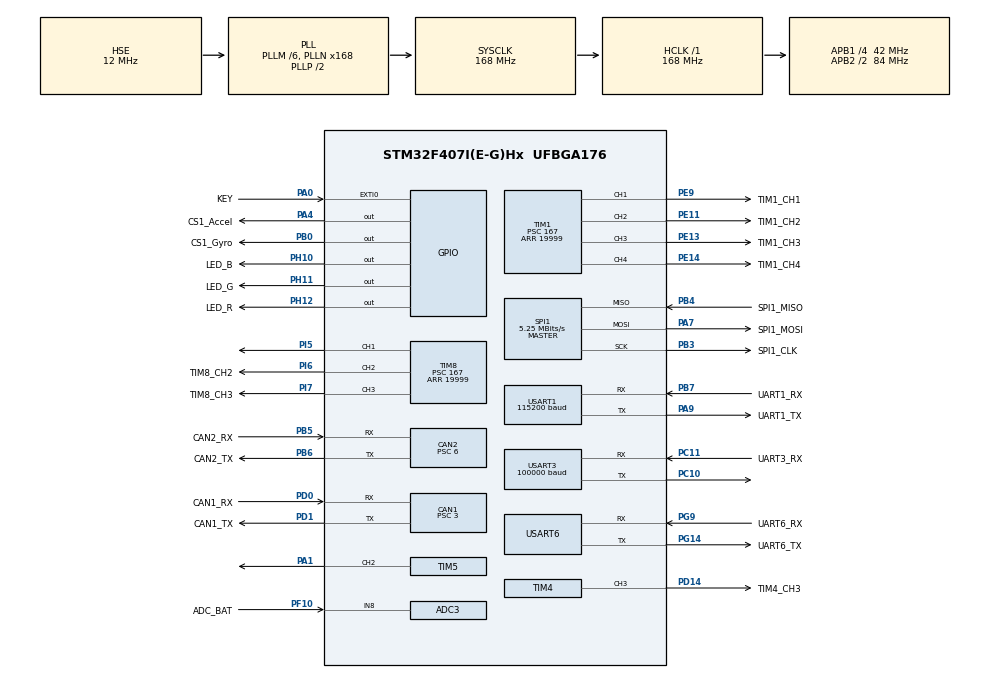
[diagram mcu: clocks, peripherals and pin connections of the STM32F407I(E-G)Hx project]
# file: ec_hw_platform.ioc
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ADC1.Channel-1\#ChannelRegularConversion=ADC_CHANNEL_TEMPSENSOR
ADC1.NbrOfConversionFlag=1
ADC1.Rank-1\#ChannelRegularConversion=1
ADC1.SamplingTime-1\#ChannelRegularConversion=ADC_SAMPLETIME_3CYCLES
ADC1.master=1
ADC3.Channel-4\#ChannelRegularConversion=ADC_CHANNEL_8
ADC3.EnableAnalogWatchDog=false
ADC3.ExternalTrigConv=ADC_EXTERNALTRIGCONV_T2_TRGO
ADC3.NbrOfConversionFlag=1
ADC3.Rank-4\#ChannelRegularConversion=1
ADC3.SamplingTime-4\#ChannelRegularConversion=ADC_SAMPLETIME_3CYCLES
CAN1.ABOM=ENABLE
CAN1.BS1=CAN_BS1_10TQ
CAN1.BS2=CAN_BS2_3TQ
CAN1.CalculateBaudRate=1000000
CAN1.CalculateTimeBit=1000
CAN1.CalculateTimeQuantum=71.42857142857143
CAN1.Prescaler=3
CAN2.ABOM=ENABLE
CAN2.BS1=CAN_BS1_3TQ
CAN2.BS2=CAN_BS2_3TQ
CAN2.CalculateBaudRate=1000000
CAN2.CalculateTimeBit=1000
CAN2.CalculateTimeQuantum=142.85714285714286
CAN2.Prescaler=6
Dma.Request0=USART1_TX
Dma.Request1=USART1_RX
Dma.Request2=USART6_RX
Dma.Request3=USART6_TX
Dma.Request4=SPI1_RX
Dma.Request5=SPI1_TX
Dma.Request6=USART3_RX
Dma.Request7=USART3_TX
Dma.SPI1_RX.4.Direction=DMA_PERIPH_TO_MEMORY
Dma.SPI1_RX.4.FIFOMode=DMA_FIFOMODE_DISABLE
Dma.SPI1_RX.4.Instance=DMA2_Stream0
Dma.SPI1_RX.4.MemDataAlignment=DMA_MDATAALIGN_BYTE
Dma.SPI1_RX.4.MemInc=DMA_MINC_ENABLE
Dma.SPI1_RX.4.Mode=DMA_NORMAL
Dma.SPI1_RX.4.PeriphDataAlignment=DMA_PDATAALIGN_BYTE
Dma.SPI1_RX.4.PeriphInc=DMA_PINC_DISABLE
Dma.SPI1_RX.4.Priority=DMA_PRIORITY_LOW
Dma.SPI1_TX.5.Direction=DMA_MEMORY_TO_PERIPH
Dma.SPI1_TX.5.FIFOMode=DMA_FIFOMODE_DISABLE
Dma.SPI1_TX.5.Instance=DMA2_Stream3
Dma.SPI1_TX.5.MemDataAlignment=DMA_MDATAALIGN_BYTE
Dma.SPI1_TX.5.MemInc=DMA_MINC_ENABLE
Dma.SPI1_TX.5.Mode=DMA_NORMAL
Dma.SPI1_TX.5.PeriphDataAlignment=DMA_PDATAALIGN_BYTE
Dma.SPI1_TX.5.PeriphInc=DMA_PINC_DISABLE
Dma.SPI1_TX.5.Priority=DMA_PRIORITY_LOW
Dma.USART1_RX.1.Direction=DMA_PERIPH_TO_MEMORY
Dma.USART1_RX.1.FIFOMode=DMA_FIFOMODE_DISABLE
Dma.USART1_RX.1.Instance=DMA2_Stream2
Dma.USART1_RX.1.MemDataAlignment=DMA_MDATAALIGN_BYTE
Dma.USART1_RX.1.MemInc=DMA_MINC_ENABLE
Dma.USART1_RX.1.Mode=DMA_NORMAL
Dma.USART1_RX.1.PeriphDataAlignment=DMA_PDATAALIGN_BYTE
Dma.USART1_RX.1.PeriphInc=DMA_PINC_DISABLE
Dma.USART1_RX.1.Priority=DMA_PRIORITY_LOW
Dma.USART1_TX.0.Direction=DMA_MEMORY_TO_PERIPH
Dma.USART1_TX.0.FIFOMode=DMA_FIFOMODE_DISABLE
Dma.USART1_TX.0.Instance=DMA2_Stream7
Dma.USART1_TX.0.MemDataAlignment=DMA_MDATAALIGN_BYTE
Dma.USART1_TX.0.MemInc=DMA_MINC_ENABLE
Dma.USART1_TX.0.Mode=DMA_NORMAL
Dma.USART1_TX.0.PeriphDataAlignment=DMA_PDATAALIGN_BYTE
Dma.USART1_TX.0.PeriphInc=DMA_PINC_DISABLE
Dma.USART1_TX.0.Priority=DMA_PRIORITY_LOW
Dma.USART3_RX.6.Direction=DMA_PERIPH_TO_MEMORY
Dma.USART3_RX.6.FIFOMode=DMA_FIFOMODE_DISABLE
Dma.USART3_RX.6.Instance=DMA1_Stream1
Dma.USART3_RX.6.MemDataAlignment=DMA_MDATAALIGN_BYTE
Dma.USART3_RX.6.MemInc=DMA_MINC_ENABLE
Dma.USART3_RX.6.Mode=DMA_NORMAL
Dma.USART3_RX.6.PeriphDataAlignment=DMA_PDATAALIGN_BYTE
Dma.USART3_RX.6.PeriphInc=DMA_PINC_DISABLE
Dma.USART3_RX.6.Priority=DMA_PRIORITY_LOW
Dma.USART3_TX.7.Direction=DMA_MEMORY_TO_PERIPH
Dma.USART3_TX.7.FIFOMode=DMA_FIFOMODE_DISABLE
Dma.USART3_TX.7.Instance=DMA1_Stream3
Dma.USART3_TX.7.MemDataAlignment=DMA_MDATAALIGN_BYTE
Dma.USART3_TX.7.MemInc=DMA_MINC_ENABLE
Dma.USART3_TX.7.Mode=DMA_NORMAL
Dma.USART3_TX.7.PeriphDataAlignment=DMA_PDATAALIGN_BYTE
Dma.USART3_TX.7.PeriphInc=DMA_PINC_DISABLE
Dma.USART3_TX.7.Priority=DMA_PRIORITY_LOW
Dma.USART6_RX.2.Direction=DMA_PERIPH_TO_MEMORY
Dma.USART6_RX.2.FIFOMode=DMA_FIFOMODE_DISABLE
Dma.USART6_RX.2.Instance=DMA2_Stream1
Dma.USART6_RX.2.MemDataAlignment=DMA_MDATAALIGN_BYTE
Dma.USART6_RX.2.MemInc=DMA_MINC_ENABLE
Dma.USART6_RX.2.Mode=DMA_NORMAL
Dma.USART6_RX.2.PeriphDataAlignment=DMA_PDATAALIGN_BYTE
Dma.USART6_RX.2.PeriphInc=DMA_PINC_DISABLE
Dma.USART6_RX.2.Priority=DMA_PRIORITY_LOW
Dma.USART6_TX.3.Direction=DMA_MEMORY_TO_PERIPH
Dma.USART6_TX.3.FIFOMode=DMA_FIFOMODE_DISABLE
Dma.USART6_TX.3.Instance=DMA2_Stream6
Dma.USART6_TX.3.MemDataAlignment=DMA_MDATAALIGN_BYTE
Dma.USART6_TX.3.MemInc=DMA_MINC_ENABLE
Dma.USART6_TX.3.Mode=DMA_NORMAL
Dma.USART6_TX.3.PeriphDataAlignment=DMA_PDATAALIGN_BYTE
Dma.USART6_TX.3.PeriphInc=DMA_PINC_DISABLE
Dma.USART6_TX.3.Priority=DMA_PRIORITY_LOW
IWDG.Prescaler=IWDG_PRESCALER_32
IWDG.Reload=511
Mcu.Family=STM32F4
Mcu.Name=STM32F407I(E-G)Hx
Mcu.Package=UFBGA176
NVIC.CAN1_RX0_IRQn=true\:0\:0\:false\:false\:true\:true\:true\:true
NVIC.CAN1_RX1_IRQn=true\:0\:0\:false\:false\:true\:true\:true\:true
NVIC.CAN2_RX0_IRQn=true\:0\:0\:false\:false\:true\:true\:true\:true
NVIC.CAN2_RX1_IRQn=true\:0\:0\:false\:false\:true\:true\:true\:true
NVIC.DMA1_Stream1_IRQn=true\:0\:0\:false\:false\:true\:false\:true\:true
NVIC.DMA1_Stream3_IRQn=true\:0\:0\:false\:false\:true\:false\:true\:true
NVIC.DMA2_Stream0_IRQn=true\:0\:0\:false\:false\:true\:false\:true\:true
NVIC.DMA2_Stream1_IRQn=true\:0\:0\:false\:false\:true\:false\:true\:true
NVIC.DMA2_Stream2_IRQn=true\:0\:0\:false\:false\:true\:false\:true\:true
NVIC.DMA2_Stream3_IRQn=true\:0\:0\:false\:false\:true\:false\:true\:true
NVIC.DMA2_Stream6_IRQn=true\:0\:0\:false\:false\:true\:false\:true\:true
NVIC.DMA2_Stream7_IRQn=true\:0\:0\:false\:false\:true\:false\:true\:true
NVIC.EXTI0_IRQn=true\:0\:0\:false\:false\:true\:true\:true\:true
NVIC.PriorityGroup=NVIC_PRIORITYGROUP_4
NVIC.TIM1_UP_TIM10_IRQn=true\:0\:0\:false\:false\:true\:true\:true\:true
NVIC.TIM6_DAC_IRQn=true\:0\:0\:false\:false\:true\:true\:true\:true
NVIC.TIM7_IRQn=true\:0\:0\:false\:false\:true\:true\:true\:true
NVIC.USART1_IRQn=true\:0\:0\:false\:false\:true\:true\:true\:true
NVIC.USART6_IRQn=true\:0\:0\:false\:false\:true\:true\:true\:true
PA0-WKUP.GPIO_Label=KEY
PA0-WKUP.GPIO_ModeDefaultEXTI=GPIO_MODE_IT_FALLING
PA0-WKUP.GPIO_PuPd=GPIO_PULLUP
PA0-WKUP.Signal=GPXTI0
PA1.Signal=S_TIM5_CH2
PA13.Mode=Serial_Wire
PA13.Signal=SYS_JTMS-SWDIO
PA14.Mode=Serial_Wire
PA14.Signal=SYS_JTCK-SWCLK
PA4.GPIO_Label=CS1_Accel
PA4.GPIO_PuPd=GPIO_PULLUP
PA4.Signal=GPIO_Output
PA7.GPIO_Label=SPI1_MOSI
PA7.Mode=Full_Duplex_Master
PA7.Signal=SPI1_MOSI
PA9.GPIO_Label=UART1_TX
PA9.Mode=Asynchronous
PA9.Signal=USART1_TX
PB0.GPIO_Label=CS1_Gyro
PB0.GPIO_PuPd=GPIO_PULLUP
PB0.Signal=GPIO_Output
PB3.GPIO_Label=SPI1_CLK
PB3.Mode=Full_Duplex_Master
PB3.Signal=SPI1_SCK
PB4.GPIO_Label=SPI1_MISO
PB4.Mode=Full_Duplex_Master
PB4.Signal=SPI1_MISO
PB5.GPIO_Label=CAN2_RX
PB5.Mode=CAN_Activate
PB5.Signal=CAN2_RX
PB6.GPIO_Label=CAN2_TX
PB6.Mode=CAN_Activate
PB6.Signal=CAN2_TX
PB7.GPIO_Label=UART1_RX
PB7.Mode=Asynchronous
PB7.Signal=USART1_RX
PC10.Mode=Asynchronous
PC10.Signal=USART3_TX
PC11.GPIO_Label=UART3_RX
PC11.Mode=Asynchronous
PC11.Signal=USART3_RX
PC8.GPIO_Label=TIM3_CH3
PC8.Signal=S_TIM3_CH3
PD0.GPIO_Label=CAN1_RX
PD0.Mode=CAN_Activate
PD0.Signal=CAN1_RX
PD1.GPIO_Label=CAN1_TX
PD1.Mode=CAN_Activate
PD1.Signal=CAN1_TX
PD14.GPIO_Label=TIM4_CH3
PD14.Signal=S_TIM4_CH3
PE11.GPIO_Label=TIM1_CH2
PE11.Signal=S_TIM1_CH2
PE13.GPIO_Label=TIM1_CH3
PE13.Signal=S_TIM1_CH3
PE14.GPIO_Label=TIM1_CH4
PE14.Signal=S_TIM1_CH4
PE9.GPIO_Label=TIM1_CH1
PE9.Signal=S_TIM1_CH1
PF10.GPIO_Label=ADC_BAT
PF10.Mode=IN8
PF10.Signal=ADC3_IN8
PG14.GPIO_Label=UART6_TX
PG14.Mode=Asynchronous
PG14.Signal=USART6_TX
PG9.GPIO_Label=UART6_RX
PG9.Mode=Asynchronous
PG9.Signal=USART6_RX
PH0-OSC_IN.Mode=HSE-External-Oscillator
PH0-OSC_IN.Signal=RCC_OSC_IN
PH1-OSC_OUT.Mode=HSE-External-Oscillator
PH1-OSC_OUT.Signal=RCC_OSC_OUT
PH10.GPIO_Label=LED_B
PH10.Signal=GPIO_Output
PH11.GPIO_Label=LED_G
PH11.Signal=GPIO_Output
PH12.GPIO_Label=LED_R
PH12.Signal=GPIO_Output
PI5.Signal=S_TIM8_CH1
PI6.GPIO_Label=TIM8_CH2
PI6.Signal=S_TIM8_CH2
PI7.GPIO_Label=TIM8_CH3
PI7.Signal=S_TIM8_CH3
ProjectManager.HeapSize=0x1000
ProjectManager.StackSize=0x4000
ProjectManager.TargetToolchain=STM32CubeIDE
RCC.48MHZClocksFreq_Value=84000000
RCC.AHBFreq_Value=168000000
RCC.APB1CLKDivider=RCC_HCLK_DIV4
RCC.APB1Freq_Value=42000000
RCC.APB1TimFreq_Value=84000000
RCC.APB2CLKDivider=RCC_HCLK_DIV2
RCC.APB2Freq_Value=84000000
RCC.APB2TimFreq_Value=168000000
RCC.CortexFreq_Value=168000000
RCC.HCLKFreq_Value=168000000
RCC.HSE_VALUE=12000000
RCC.HSI_VALUE=16000000
RCC.LSE_VALUE=32768
RCC.PLLM=6
RCC.PLLN=168
RCC.PLLSourceVirtual=RCC_PLLSOURCE_HSE
RCC.SYSCLKFreq_VALUE=168000000
RCC.SYSCLKSource=RCC_SYSCLKSOURCE_PLLCLK
RCC.VCOOutputFreq_Value=336000000
SH.S_TIM1_CH1.0=TIM1_CH1,PWM Generation1 CH1
SH.S_TIM1_CH2.0=TIM1_CH2,PWM Generation2 CH2
SH.S_TIM1_CH3.0=TIM1_CH3,PWM Generation3 CH3
SH.S_TIM1_CH4.0=TIM1_CH4,PWM Generation4 CH4
SH.S_TIM3_CH3.0=TIM3_CH3
SH.S_TIM4_CH3.0=TIM4_CH3,PWM Generation3 CH3
SH.S_TIM5_CH2.0=TIM5_CH2,PWM Generation2 CH2
SH.S_TIM8_CH1.0=TIM8_CH1,PWM Generation1 CH1
SH.S_TIM8_CH2.0=TIM8_CH2,PWM Generation2 CH2
SH.S_TIM8_CH3.0=TIM8_CH3,PWM Generation3 CH3
SPI1.BaudRatePrescaler=SPI_BAUDRATEPRESCALER_16
SPI1.CLKPhase=SPI_PHASE_2EDGE
SPI1.CalculateBaudRate=5.25 MBits/s
SPI1.Direction=SPI_DIRECTION_2LINES
SPI1.Mode=SPI_MODE_MASTER
SPI1.VirtualType=VM_MASTER
TIM1.Channel-PWM\ Generation1\ CH1=TIM_CHANNEL_1
TIM1.Channel-PWM\ Generation2\ CH2=TIM_CHANNEL_2
TIM1.Channel-PWM\ Generation3\ CH3=TIM_CHANNEL_3
TIM1.Channel-PWM\ Generation4\ CH4=TIM_CHANNEL_4
TIM1.Period=19999
TIM1.Prescaler=167
TIM1.Pulse-PWM\ Generation1\ CH1=2000
TIM1.Pulse-PWM\ Generation2\ CH2=2000
TIM1.Pulse-PWM\ Generation3\ CH3=2000
TIM1.Pulse-PWM\ Generation4\ CH4=2000
TIM3.TIM_MasterOutputTrigger=TIM_TRGO_UPDATE
TIM4.AutoReloadPreload=TIM_AUTORELOAD_PRELOAD_ENABLE
TIM4.Channel-PWM\ Generation3\ CH3=TIM_CHANNEL_3
TIM4.Period=20999
TIM4.Prescaler=0
TIM5.Channel-PWM\ Generation2\ CH2=TIM_CHANNEL_2
TIM5.Period=500
TIM6.Period=999
TIM6.Prescaler=83
TIM7.Period=999
TIM7.Prescaler=83
TIM8.Channel-PWM\ Generation1\ CH1=TIM_CHANNEL_1
TIM8.Channel-PWM\ Generation2\ CH2=TIM_CHANNEL_2
TIM8.Channel-PWM\ Generation3\ CH3=TIM_CHANNEL_3
TIM8.Period=19999
TIM8.Prescaler=167
TIM8.Pulse-PWM\ Generation1\ CH1=2000
TIM8.Pulse-PWM\ Generation2\ CH2=2000
TIM8.Pulse-PWM\ Generation3\ CH3=2000
USART1.BaudRate=115200
USART1.VirtualMode=VM_ASYNC
USART3.BaudRate=100000
USART3.Parity=PARITY_EVEN
USART3.VirtualMode=VM_ASYNC
USART6.VirtualMode=VM_ASYNC
VP_ADC1_TempSens_Input.Mode=IN-TempSens
VP_ADC1_Vref_Input.Mode=IN-Vrefint
VP_IWDG_VS_IWDG.Mode=IWDG_Activate
VP_TIM1_VS_ClockSourceINT.Mode=Internal
VP_TIM3_VS_ClockSourceINT.Mode=Internal
VP_TIM4_VS_ClockSourceINT.Mode=Internal
VP_TIM5_VS_ClockSourceINT.Mode=Internal
VP_TIM6_VS_ClockSourceINT.Mode=Enable_Timer
VP_TIM7_VS_ClockSourceINT.Mode=Enable_Timer
VP_TIM8_VS_ClockSourceINT.Mode=Internal
board=custom

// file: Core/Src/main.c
/* USER CODE BEGIN Header */
/**
  ******************************************************************************
  * @file           : main.c
  * @brief          : Main program body
  ******************************************************************************
  * @attention
  *
  * Copyright (c) 2023 STMicroelectronics.
  * All rights reserved.
  *
  * This software is licensed under terms that can be found in the LICENSE file
  * in the root directory of this software component.
  * If no LICENSE file comes with this software, it is provided AS-IS.
  *
  ******************************************************************************
  */
/* USER CODE END Header */
#include "main.h"
#include "adc.h"
#include "can.h"
#include "dma.h"
#include "iwdg.h"
#include "spi.h"
#include "tim.h"
#include "usart.h"
#include "gpio.h"

/* USER CODE BEGIN PV */
//uint16_t ADC_Value;
//uint16_t pwmValue=0;

//uint8_t TxData[10]="hello";
//uint8_t RxData[10];

//uint16_t psc=0,pwm=0;
//#define MIN_BUZZER_PWM 10000
//#define MAX_BUZZER_PWM 20000
//#define MAX_PSC 1000
/* USER CODE END PV */

void SystemClock_Config(void);

int main(void)
{

  /* MCU Configuration--------------------------------------------------------*/

  /* Reset of all peripherals, Initializes the Flash interface and the Systick. */
  HAL_Init();

  /* Configure the system clock */
  SystemClock_Config();

  /* Initialize all configured peripherals */
  MX_GPIO_Init();
  MX_DMA_Init();
  MX_TIM1_Init();
  MX_ADC3_Init();
  MX_CAN1_Init();
  MX_IWDG_Init();
  MX_TIM3_Init();
  MX_TIM4_Init();
  MX_TIM5_Init();
  MX_TIM6_Init();
  MX_TIM7_Init();
  MX_CAN2_Init();
  MX_TIM8_Init();
  MX_SPI1_Init();
  MX_USART1_UART_Init();
  MX_USART6_UART_Init();
  MX_USART3_UART_Init();
  MX_ADC1_Init();
  /* USER CODE BEGIN 2 */
//  HAL_TIM_Base_Start_IT(&htim1);
//  HAL_UART_Init(&huart1);
//  HAL_UART_Receive_IT(&huart1,RxData,5);

//    HAL_GPIO_WritePin(LED_R_GPIO_Port,LED_R_Pin,GPIO_PIN_RESET);
//    HAL_GPIO_WritePin(LED_G_GPIO_Port,LED_G_Pin,GPIO_PIN_RESET);
//    HAL_GPIO_WritePin(LED_B_GPIO_Port,LED_B_Pin,GPIO_PIN_RESET);

//    HAL_TIM_PWM_Start(&htim5,TIM_CHANNEL_1);
//    HAL_TIM_PWM_Start(&htim5,TIM_CHANNEL_2);
//    HAL_TIM_PWM_Start(&htim5,TIM_CHANNEL_3);

//    HAL_TIM_Base_Start(&htim4);
//    HAL_TIM_PWM_Start(&htim4,TIM_CHANNEL_3);

//    HAL_TIM_Base_Start(&htim1);
//    HAL_TIM_Base_Start(&htim8);
//    HAL_TIM_PWM_Start(&htim1,TIM_CHANNEL_1);
//    HAL_TIM_PWM_Start(&htim1,TIM_CHANNEL_2);
//    HAL_TIM_PWM_Start(&htim1,TIM_CHANNEL_3);
//    HAL_TIM_PWM_Start(&htim1,TIM_CHANNEL_4);
//    HAL_TIM_PWM_Start(&htim8,TIM_CHANNEL_1);
//    HAL_TIM_PWM_Start(&htim8,TIM_CHANNEL_2);
//    HAL_TIM_PWM_Start(&htim8,TIM_CHANNEL_3);

  /* USER CODE END 2 */

  /* Infinite loop */
  /* USER CODE BEGIN WHILE */
  while (1)
  {
//      __HAL_TIM_SetCompare(&htim1,TIM_CHANNEL_1,pwm);

//      pwm++;
//      psc++;
//
//      if(pwm > MAX_BUZZER_PWM)
//      {
//          pwm = MIN_BUZZER_PWM;
//      }
//      if(psc > MAX_PSC)
//      {
//          psc = 0;
//      }
//      buzzer_on(psc, pwm);
//      HAL_Delay(1);

//      HAL_UART_Transmit_IT(&huart1,TxData,5);
//      HAL_Delay(1000);

//      HAL_UART_Transmit(&huart1,TxData,5,500);
//      HAL_UART_Receive(&huart1,RxData,5,500);
//      if(RxData[0]=='1'){
//          HAL_GPIO_TogglePin(LED_B_GPIO_Port,LED_B_Pin);
//          HAL_GPIO_TogglePin(LED_G_GPIO_Port,LED_G_Pin);
//          HAL_GPIO_TogglePin(LED_R_GPIO_Port,LED_R_Pin);
//          RxData[0]=0;
//      }

//      HAL_ADC_Start(&hadc3);
//      HAL_ADC_PollForConversion(&hadc3,50);
//      if(HAL_IS_BIT_SET(HAL_ADC_GetState(&hadc3),HAL_ADC_STATE_REG_EOC)){
//          ADC_Value= HAL_ADC_GetValue(&hadc3);
//      }
//      HAL_Delay(500);

//      while (pwmValue<500){
//          ++pwmValue;
//          __HAL_TIM_SetCompare(&htim5,TIM_CHANNEL_1,pwmValue);
//          __HAL_TIM_SetCompare(&htim5,TIM_CHANNEL_2,pwmValue);
//          __HAL_TIM_SetCompare(&htim5,TIM_CHANNEL_3,pwmValue);
//          HAL_Delay(10);
//      }
//
//      while (pwmValue>0){
//          --pwmValue;
//          __HAL_TIM_SetCompare(&htim5,TIM_CHANNEL_1,pwmValue);
//          __HAL_TIM_SetCompare(&htim5,TIM_CHANNEL_2,pwmValue);
//          __HAL_TIM_SetCompare(&htim5,TIM_CHANNEL_3,pwmValue);
//          HAL_Delay(10);
//      }
//
//      HAL_Delay(5000);

    /* USER CODE END WHILE */

  }
}

void SystemClock_Config(void)
{
  RCC_OscInitTypeDef RCC_OscInitStruct = {0};
  RCC_ClkInitTypeDef RCC_ClkInitStruct = {0};

  /** Configure the main internal regulator output voltage
  */
  __HAL_RCC_PWR_CLK_ENABLE();
  __HAL_PWR_VOLTAGESCALING_CONFIG(PWR_REGULATOR_VOLTAGE_SCALE1);

  /** Initializes the RCC Oscillators according to the specified parameters
  * in the RCC_OscInitTypeDef structure.
  */
  RCC_OscInitStruct.OscillatorType = RCC_OSCILLATORTYPE_LSI|RCC_OSCILLATORTYPE_HSE;
  RCC_OscInitStruct.HSEState = RCC_HSE_ON;
  RCC_OscInitStruct.LSIState = RCC_LSI_ON;
  RCC_OscInitStruct.PLL.PLLState = RCC_PLL_ON;
  RCC_OscInitStruct.PLL.PLLSource = RCC_PLLSOURCE_HSE;
  RCC_OscInitStruct.PLL.PLLM = 6;
  RCC_OscInitStruct.PLL.PLLN = 168;
  RCC_OscInitStruct.PLL.PLLP = RCC_PLLP_DIV2;
  RCC_OscInitStruct.PLL.PLLQ = 4;
  if (HAL_RCC_OscConfig(&RCC_OscInitStruct) != HAL_OK)
  {
    Error_Handler();
  }

  /** Initializes the CPU, AHB and APB buses clocks
  */
  RCC_ClkInitStruct.ClockType = RCC_CLOCKTYPE_HCLK|RCC_CLOCKTYPE_SYSCLK
                              |RCC_CLOCKTYPE_PCLK1|RCC_CLOCKTYPE_PCLK2;
  RCC_ClkInitStruct.SYSCLKSource = RCC_SYSCLKSOURCE_PLLCLK;
  RCC_ClkInitStruct.AHBCLKDivider = RCC_SYSCLK_DIV1;
  RCC_ClkInitStruct.APB1CLKDivider = RCC_HCLK_DIV4;
  RCC_ClkInitStruct.APB2CLKDivider = RCC_HCLK_DIV2;

  if (HAL_RCC_ClockConfig(&RCC_ClkInitStruct, FLASH_LATENCY_5) != HAL_OK)
  {
    Error_Handler();
  }
}

/* USER CODE BEGIN 4 */
//void HAL_TIM_PeriodElapsedCallback(TIM_HandleTypeDef *htim){
//    if(htim==&htim1){
//        HAL_GPIO_TogglePin(LED_R_GPIO_Port,LED_R_Pin);
//        HAL_GPIO_TogglePin(LED_G_GPIO_Port,LED_G_Pin);
//        HAL_GPIO_TogglePin(LED_B_GPIO_Port,LED_B_Pin);
//    }
//}

//void HAL_TIM_PeriodElapsedCallback(TIM_HandleTypeDef *htim) {
//    if (htim->Instance == htim6.Instance) {
//// 因为有很多个定时器，我们�?要区别一下是哪一个定时器触发了中�?
//// 这里是tim6触发�?
//        HAL_NVIC_DisableIRQ(TIM6_DAC_IRQn);
//        MainControlLoop();
//        HAL_NVIC_EnableIRQ(TIM6_DAC_IRQn);
//    }
//    if(htim->Instance == htim7.Instance) {
//// 这里是tim7触发�?
//        Count();
//        Remote::remote.Handle();
//    }
//}

//void HAL_GPIO_EXTI_Callback(uint16_t GPIO_PIN){
//    switch(GPIO_PIN){
//        case KEY_Pin:
//            HAL_GPIO_TogglePin(LED_B_GPIO_Port,LED_B_Pin);
//            HAL_GPIO_TogglePin(LED_G_GPIO_Port,LED_G_Pin);
//            HAL_GPIO_TogglePin(LED_R_GPIO_Port,LED_R_Pin);
//            break;
//    }
//}

//void HAL_UART_RxCpltCallback(UART_HandleTypeDef *huart){
//    if(huart==&huart1){
//        HAL_UART_Receive_IT(&huart1,RxData,5);
//        if(RxData[0]=='h'){
//            HAL_GPIO_TogglePin(LED_B_GPIO_Port,LED_B_Pin);
//            HAL_GPIO_TogglePin(LED_G_GPIO_Port,LED_G_Pin);
//            HAL_GPIO_TogglePin(LED_R_GPIO_Port,LED_R_Pin);
//            RxData[0]=0;
//            HAL_Delay(100);
//        }
//    }
//}

//void buzzer_on(uint16_t psc,uint16_t pwm)
//{
//    htim4.Instance->PSC=psc;
//    __HAL_TIM_SetCompare(&htim4,TIM_CHANNEL_3,pwm);
//}

//void canFilterInit(void) {
//    CAN_FilterTypeDef filter;
//    filter.FilterActivation = ENABLE;
//    filter.FilterMode = CAN_FILTERMODE_IDMASK;
//    filter.FilterScale = CAN_FILTERSCALE_32BIT;
//    filter.FilterIdHigh = 0x0000;
//    filter.FilterIdLow = 0x0000;
//    filter.FilterMaskIdHigh = 0x0000;
//    filter.FilterMaskIdLow = 0x0000;
//    filter.FilterFIFOAssignment = CAN_RX_FIFO0;
//    filter.SlaveStartFilterBank = 14;
//    filter.FilterBank = 0;
//    HAL_CAN_ConfigFilter(&hcan1, &filter);
//    HAL_CAN_Start(&hcan1);
//    HAL_CAN_ActivateNotification(&hcan1, CAN_IT_RX_FIFO0_MSG_PENDING);
//    filter.FilterBank = 14;
//    HAL_CAN_ConfigFilter(&hcan2, &filter);
//    HAL_CAN_Start(&hcan2);
//    HAL_CAN_ActivateNotification(&hcan2, CAN_IT_RX_FIFO0_MSG_PENDING);
//}

//void BMI088_read(fp32 gyro[3], fp32 accel[3], fp32 *temperate)
//{
//    uint8_t buf[8] = {0, 0, 0, 0, 0, 0};
//    int16_t bmi088_raw_temp;
//    BMI088_accel_read_muli_reg(BMI088_ACCEL_XOUT_L, buf, 6);
//    bmi088_raw_temp = (int16_t)((buf[1]) << 8) | buf[0];
//    accel[0] = bmi088_raw_temp * BMI088_ACCEL_SEN;
//    bmi088_raw_temp = (int16_t)((buf[3]) << 8) | buf[2];
//    accel[1] = bmi088_raw_temp * BMI088_ACCEL_SEN;
//    bmi088_raw_temp = (int16_t)((buf[5]) << 8) | buf[4];
//    accel[2] = bmi088_raw_temp * BMI088_ACCEL_SEN;
//    BMI088_gyro_read_muli_reg(BMI088_GYRO_CHIP_ID, buf, 8);
//    if(buf[0] == BMI088_GYRO_CHIP_ID_VALUE)
//    {
//        bmi088_raw_temp = (int16_t)((buf[3]) << 8) | buf[2];
//        gyro[0] = bmi088_raw_temp * BMI088_GYRO_SEN;
//        bmi088_raw_temp = (int16_t)((buf[5]) << 8) | buf[4];
//        gyro[1] = bmi088_raw_temp * BMI088_GYRO_SEN;
//        bmi088_raw_temp = (int16_t)((buf[7]) << 8) | buf[6];
//        gyro[2] = bmi088_raw_temp * BMI088_GYRO_SEN;
//    }
//
//    BMI088_accel_read_muli_reg(BMI088_TEMP_M, buf, 2);
//    bmi088_raw_temp = (int16_t)((buf[0] << 3) | (buf[1] >> 5));
//    if (bmi088_raw_temp > 1023)
//    {
//        bmi088_raw_temp -= 2048;
//    }
//    *temperate = bmi088_raw_temp * BMI088_TEMP_FACTOR + BMI088_TEMP_OFFSET;
//}
/* USER CODE END 4 */

void Error_Handler(void)
{
  __disable_irq();
  while (1)
  {
  }
}
